# S6E1A1 register map
File version: 1.1
Registers are 8-bit, read-write, reset 0x0 unless marked. A register's access mark holds for its fields unless they carry their own. Offsets are from the block's base; [hi:lo] are bit positions; {n}, {i} and the like mark numbered series; 'fields as' and 'values as' point back to an identical list.

## GPIO — General-purpose I/O ports
Base 0x40033000
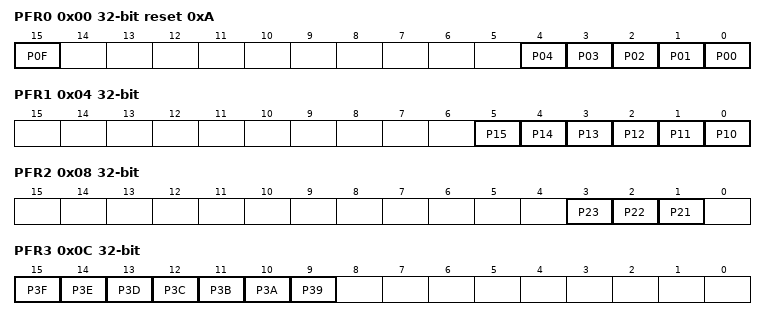
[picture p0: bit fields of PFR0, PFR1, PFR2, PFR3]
0x00 PFR0 32-bit reset 0xA — Port Function Setting Register 0
  [15] P0F — Bit15 of PFR0
  [n] P{n:02} (n=0..4) — Bit{n} of PFR0
0x04 PFR1 32-bit — Port Function Setting Register 1
  [n-10] P{n} (n=10..15) — Bit{n-10} of PFR1
0x08 PFR2 32-bit — Port Function Setting Register 2
  [3] P23 — Bit3 of PFR2
  [2] P22 — Bit2 of PFR2
  [1] P21 — Bit1 of PFR2
0x0C PFR3 32-bit — Port Function Setting Register 3
  [15] P3F — Bit15 of PFR3
  [14] P3E — Bit14 of PFR3
  [13] P3D — Bit13 of PFR3
  [12] P3C — Bit12 of PFR3
  [11] P3B — Bit11 of PFR3
  [10] P3A — Bit10 of PFR3
  [9] P39 — Bit9 of PFR3
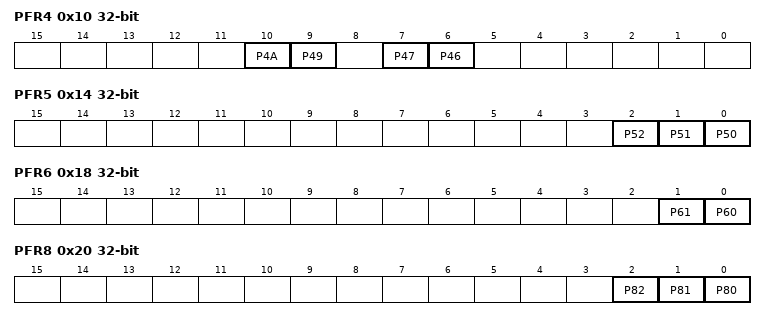
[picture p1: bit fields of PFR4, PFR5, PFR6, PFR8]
0x10 PFR4 32-bit — Port Function Setting Register 4
  [10] P4A — Bit10 of PFR4
  [9] P49 — Bit9 of PFR4
  [7] P47 — Bit7 of PFR4
  [6] P46 — Bit6 of PFR4
0x14 PFR5 32-bit — Port Function Setting Register 5
  [2] P52 — Bit2 of PFR5
  [1] P51 — Bit1 of PFR5
  [0] P50 — Bit0 of PFR5
0x18 PFR6 32-bit — Port Function Setting Register 6
  [1] P61 — Bit1 of PFR6
  [0] P60 — Bit0 of PFR6
0x20 PFR8 32-bit — Port Function Setting Register 8
  [2] P82 — Bit2 of PFR8
  [1] P81 — Bit1 of PFR8
  [0] P80 — Bit0 of PFR8
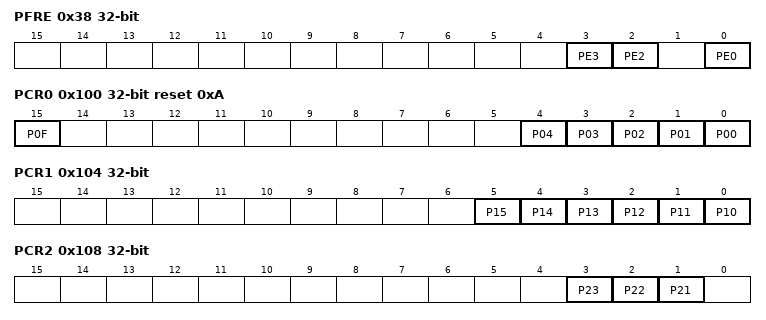
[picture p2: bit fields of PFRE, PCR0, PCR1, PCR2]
0x38 PFRE 32-bit — Port Function Setting Register E
  [3] PE3 — Bit3 of PFRE
  [2] PE2 — Bit2 of PFRE
  [0] PE0 — Bit0 of PFRE
0x100 PCR0 32-bit reset 0xA — Pull-up Setting Register 0
  [15] P0F — Bit15 of PFR0
  [n] P{n:02} (n=0..4) — Bit{n} of PFR0
0x104 PCR1 32-bit — Pull-up Setting Register 1
  [n-10] P{n} (n=10..15) — Bit{n-10} of PFR1
0x108 PCR2 32-bit — Pull-up Setting Register 2
  fields as PFR2
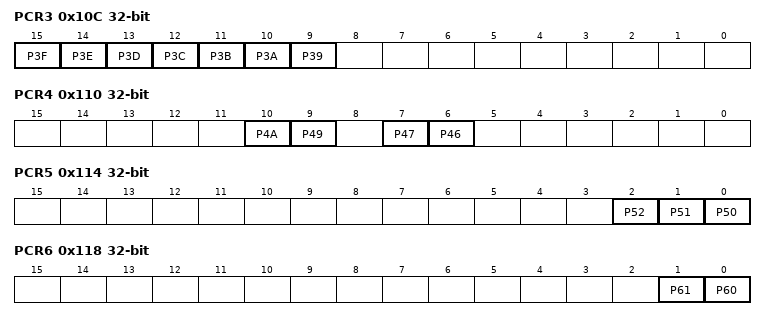
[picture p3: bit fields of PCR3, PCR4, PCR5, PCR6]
0x10C PCR3 32-bit — Pull-up Setting Register 3
  fields as PFR3
0x110 PCR4 32-bit — Pull-up Setting Register 4
  fields as PFR4
0x114 PCR5 32-bit — Pull-up Setting Register 5
  fields as PFR5
0x118 PCR6 32-bit — Pull-up Setting Register 6
  [1] P61 — Bit1 of PFR6
  [0] P60 — Bit0 of PFR6
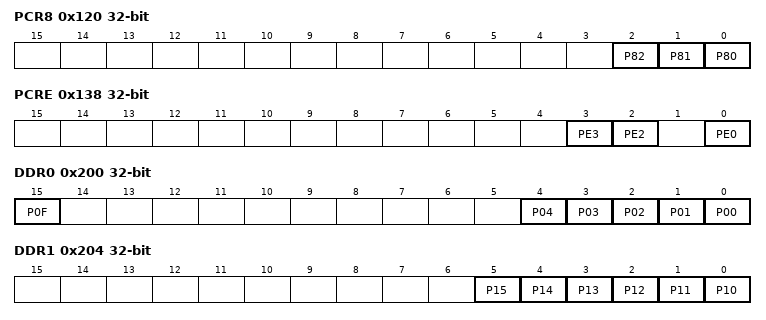
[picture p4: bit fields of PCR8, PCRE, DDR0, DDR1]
0x120 PCR8 32-bit — Pull-up Setting Register 8
  fields as PFR8
0x138 PCRE 32-bit — Pull-up Setting Register E
  fields as PFRE
0x200 DDR0 32-bit — Port input/output Direction Setting Register 0
  [15] P0F — Bit15 of DDR0
  [n] P{n:02} (n=0..4) — Bit{n} of DDR0
0x204 DDR1 32-bit — Port input/output Direction Setting Register 1
  [n-10] P{n} (n=10..15) — Bit{n-10} of PFR1
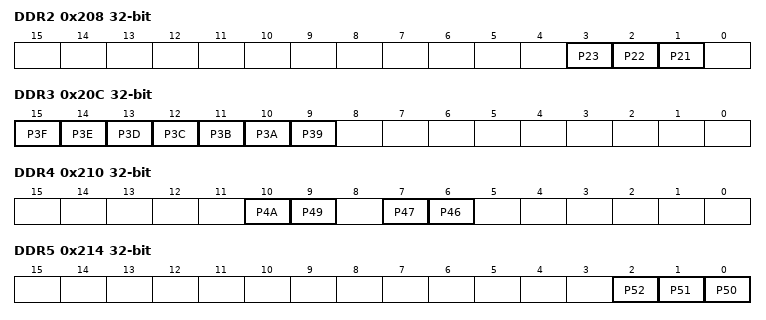
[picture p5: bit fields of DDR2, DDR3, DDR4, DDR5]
0x208 DDR2 32-bit — Port input/output Direction Setting Register 2
  fields as PFR2
0x20C DDR3 32-bit — Port input/output Direction Setting Register 3
  fields as PFR3
0x210 DDR4 32-bit — Port input/output Direction Setting Register 4
  fields as PFR4
0x214 DDR5 32-bit — Port input/output Direction Setting Register 5
  fields as PFR5
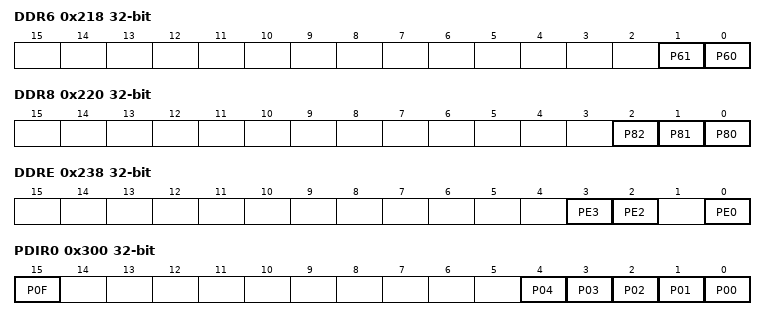
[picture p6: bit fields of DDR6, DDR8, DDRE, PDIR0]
0x218 DDR6 32-bit — Port input/output Direction Setting Register 6
  [1] P61 — Bit1 of PFR6
  [0] P60 — Bit0 of PFR6
0x220 DDR8 32-bit — Port input/output Direction Setting Register 8
  fields as PFR8
0x238 DDRE 32-bit — Port input/output Direction Setting Register E
  fields as PFRE
0x300 PDIR0 32-bit ro — Port Input Data Register 0
  [15] P0F — Bit15 of PDIR0
  [n] P{n:02} (n=0..4) — Bit{n} of PDIR0
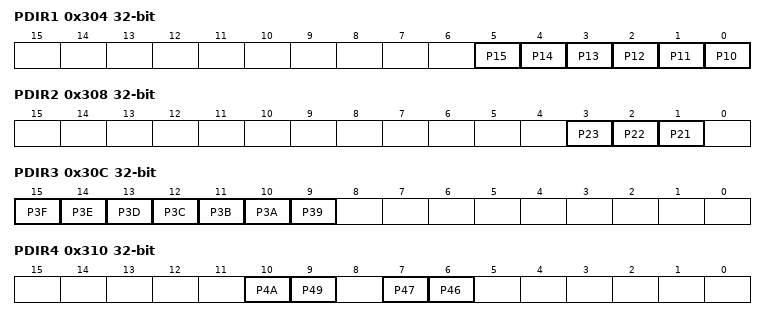
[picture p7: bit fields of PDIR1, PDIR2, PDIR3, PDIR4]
0x304 PDIR1 32-bit ro — Port Input Data Register 1
  [n-10] P{n} (n=10..15) — Bit{n-10} of PDIR1
0x308 PDIR2 32-bit ro — Port Input Data Register 2
  [3] P23 — Bit3 of PDIR2
  [2] P22 — Bit2 of PDIR2
  [1] P21 — Bit1 of PDIR2
0x30C PDIR3 32-bit ro — Port Input Data Register 3
  [15] P3F — Bit15 of PDIR3
  [14] P3E — Bit14 of PDIR3
  [13] P3D — Bit13 of PDIR3
  [12] P3C — Bit12 of PDIR3
  [11] P3B — Bit11 of PDIR3
  [10] P3A — Bit10 of PDIR3
  [9] P39 — Bit9 of PDIR3
0x310 PDIR4 32-bit ro — Port Input Data Register 4
  [10] P4A — Bit10 of PDIR4
  [9] P49 — Bit9 of PDIR4
  [7] P47 — Bit7 of PDIR4
  [6] P46 — Bit6 of PDIR4
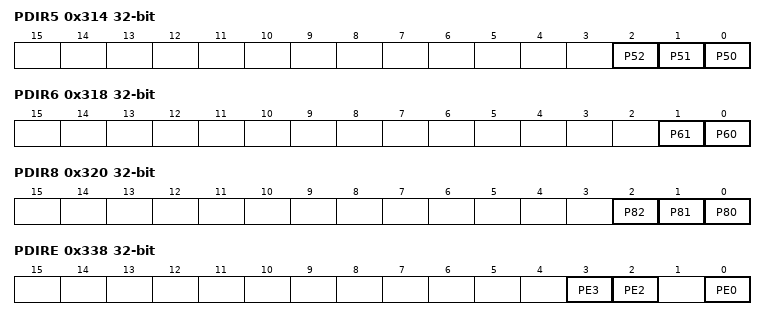
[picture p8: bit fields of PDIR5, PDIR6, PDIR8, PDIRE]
0x314 PDIR5 32-bit ro — Port Input Data Register 5
  [2] P52 — Bit2 of PDIR5
  [1] P51 — Bit1 of PDIR5
  [0] P50 — Bit0 of PDIR5
0x318 PDIR6 32-bit ro — Port Input Data Register 6
  [1] P61 — Bit1 of PDIR6
  [0] P60 — Bit0 of PDIR6
0x320 PDIR8 32-bit ro — Port Input Data Register 8
  [2] P82 — Bit2 of PDIR8
  [1] P81 — Bit1 of PDIR8
  [0] P80 — Bit0 of PDIR8
0x338 PDIRE 32-bit ro — Port Input Data Register E
  [3] PE3 — Bit3 of PDIRE
  [2] PE2 — Bit2 of PDIRE
  [0] PE0 — Bit0 of PDIRE
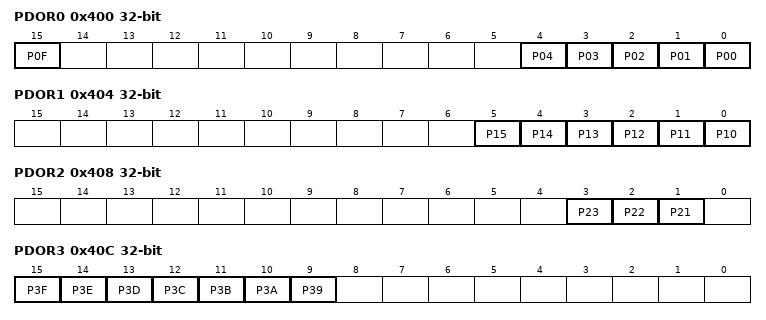
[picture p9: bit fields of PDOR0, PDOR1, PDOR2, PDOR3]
0x400 PDOR0 32-bit — Port Output Data Register 0
  [15] P0F — Bit15 of DDR0
  [n] P{n:02} (n=0..4) — Bit{n} of DDR0
0x404 PDOR1 32-bit — Port Output Data Register 1
  [n-10] P{n} (n=10..15) — Bit{n-10} of PFR1
0x408 PDOR2 32-bit — Port Output Data Register 2
  fields as PFR2
0x40C PDOR3 32-bit — Port Output Data Register 3
  fields as PFR3
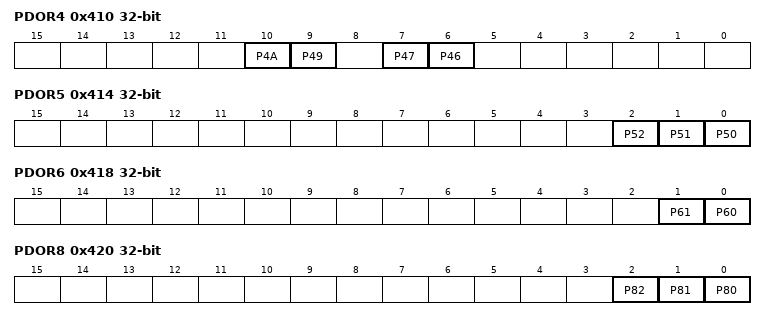
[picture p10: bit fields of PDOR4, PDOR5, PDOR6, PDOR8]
0x410 PDOR4 32-bit — Port Output Data Register 4
  fields as PFR4
0x414 PDOR5 32-bit — Port Output Data Register 5
  fields as PFR5
0x418 PDOR6 32-bit — Port Output Data Register 6
  [1] P61 — Bit1 of PFR6
  [0] P60 — Bit0 of PFR6
0x420 PDOR8 32-bit — Port Output Data Register 8
  fields as PFR8
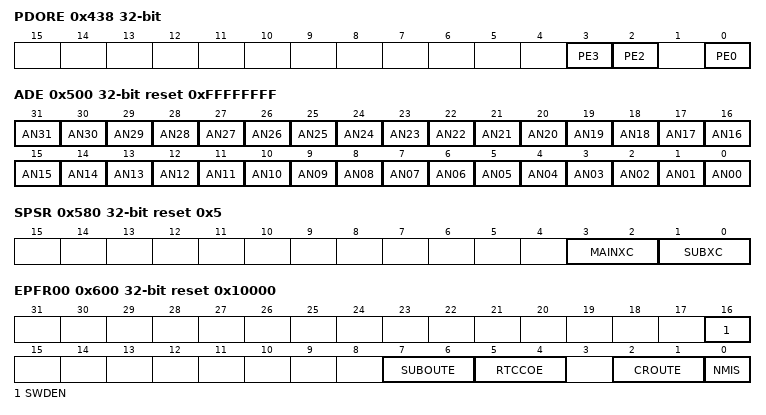
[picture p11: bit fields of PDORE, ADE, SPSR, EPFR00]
0x438 PDORE 32-bit — Port Output Data Register E
  fields as PFRE
0x500 ADE 32-bit reset 0xFFFFFFFF — Analog Input Setting Register
  [31] AN31 — Analog Input Ch.31 Setting Register
  [30] AN30 — Analog Input Ch.30 Setting Register
  [29] AN29 — Analog Input Ch.29 Setting Register
  [28] AN28 — Analog Input Ch.28 Setting Register
  [27] AN27 — Analog Input Ch.27 Setting Register
  [26] AN26 — Analog Input Ch.26 Setting Register
  [25] AN25 — Analog Input Ch.25 Setting Register
  [24] AN24 — Analog Input Ch.24 Setting Register
  [23] AN23 — Analog Input Ch.23 Setting Register
  [22] AN22 — Analog Input Ch.22 Setting Register
  [21] AN21 — Analog Input Ch.21 Setting Register
  [20] AN20 — Analog Input Ch.20 Setting Register
  [19] AN19 — Analog Input Ch.19 Setting Register
  [18] AN18 — Analog Input Ch.18 Setting Register
  [17] AN17 — Analog Input Ch.17 Setting Register
  [16] AN16 — Analog Input Ch.16 Setting Register
  [15] AN15 — Analog Input Ch.15 Setting Register
  [14] AN14 — Analog Input Ch.14 Setting Register
  [13] AN13 — Analog Input Ch.13 Setting Register
  [12] AN12 — Analog Input Ch.12 Setting Register
  [11] AN11 — Analog Input Ch.11 Setting Register
  [10] AN10 — Analog Input Ch.10 Setting Register
  [9] AN09 — Analog Input Ch.9 Setting Register
  [8] AN08 — Analog Input Ch.8 Setting Register
  [7] AN07 — Analog Input Ch.7 Setting Register
  [6] AN06 — Analog Input Ch.6 Setting Register
  [5] AN05 — Analog Input Ch.5 Setting Register
  [4] AN04 — Analog Input Ch.4 Setting Register
  [3] AN03 — Analog Input Ch.3 Setting Register
  [2] AN02 — Analog Input Ch.2 Setting Register
  [1] AN01 — Analog Input Ch.1 Setting Register
  [0] AN00 — Analog Input Ch.0 Setting Register
0x580 SPSR 32-bit reset 0x5 — Special port setting register
  [3:2] MAINXC — Main Clock (Oscillation) Pin Setting Register
  [1:0] SUBXC — Sub Clock (Oscillation) Pin Setting Register
0x600 EPFR00 32-bit reset 0x10000 — Extended Pin Function Setting Register 00
  [16] SWDEN — Serial Wire Debug Function Select bit 0
  [7:6] SUBOUTE — Sub clock divide output function select bit
  [5:4] RTCCOE — RTC clock output select bit
  [2:1] CROUTE — Internal high-speed CR Oscillation Output Function Select bit
  [0] NMIS — NMIX Function Select bit
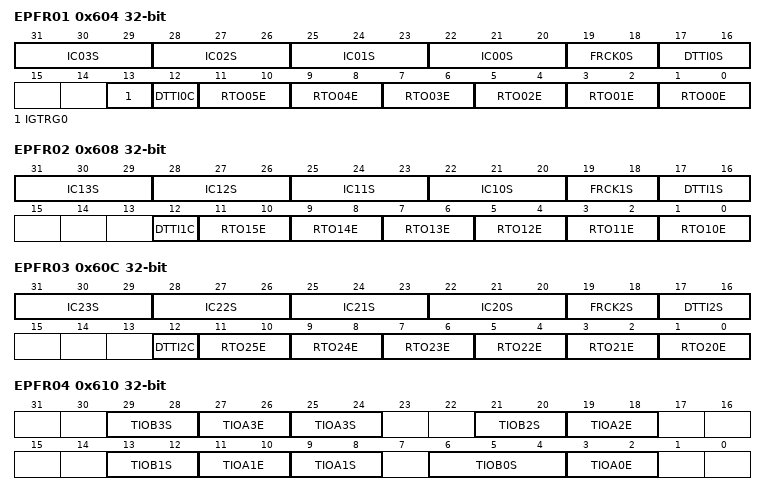
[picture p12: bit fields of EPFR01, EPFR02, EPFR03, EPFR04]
0x604 EPFR01 32-bit — Extended Pin Function Setting Register 01
  [3n+22:3n+20] IC{n:02}S (n=0..3) — IC{n:02} Input Select bits
  [19:18] FRCK0S — FRCK0 Input Select bits
  [17:16] DTTI0S — DTTIX0 Input Select bits
  [13] IGTRG0 — IGTRG0 Input Select bit
  [12] DTTI0C — DTTIX0 Function Select bit
  [2n+1:2n] RTO{n:02}E (n=0..5) — RTO{n:02} Output Select bits
0x608 EPFR02 32-bit — Extended Pin Function Setting Register 02
  [3n-8:3n-10] IC{n}S (n=10..13) — IC{n} Input Select bits
  [19:18] FRCK1S — FRCK1 Input Select bits
  [17:16] DTTI1S — DTTIX1 Input Select bits
  [12] DTTI1C — DTTIX1 Function Select bit
  [2n-19:2n-20] RTO{n}E (n=11..15) — RTO{n} Output Select bits
  [1:0] RTO10E — RTO00 Output Select bits
0x60C EPFR03 32-bit — Extended Pin Function Setting Register 03
  [3n-38:3n-40] IC{n}S (n=20..23) — IC{n} Input Select bits
  [19:18] FRCK2S — FRCK2 Input Select bits
  [17:16] DTTI2S — DTTIX2 Input Select bits
  [12] DTTI2C — DTTIX2 Function Select bit
  [2n-39:2n-40] RTO{n}E (n=20..25) — RTO{n} Output Select bits
0x610 EPFR04 32-bit — Extended Pin Function Setting Register 04
  [29:28] TIOB3S — TIOB3 Input Select bits
  [8n+3:8n+2] TIOA{n}E (n=0..3) — TIOA{n} Output Select bits
  [25:24] TIOA3S — TIOA3 Input Select bits
  [21:20] TIOB2S — TIOB2 Input Select bits
  [13:12] TIOB1S — TIOB1 Input Select bits
  [9:8] TIOA1S — TIOA1 Input Select bits
  [6:4] TIOB0S — TIOB0 Input Select bits
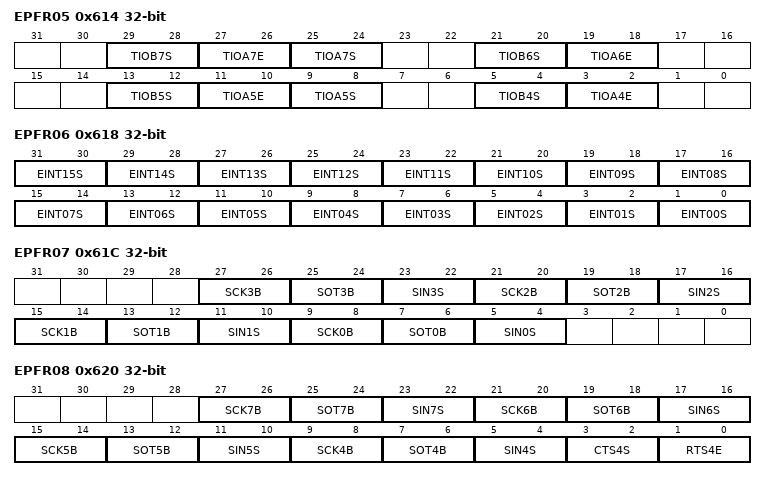
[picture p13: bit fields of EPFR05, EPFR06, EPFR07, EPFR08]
0x614 EPFR05 32-bit — Extended Pin Function Setting Register 05
  [8n-27:8n-28] TIOB{n}S (n=4..7) — TIOB{n} Input Select bits
  [8n-29:8n-30] TIOA{n}E (n=4..7) — TIOA{n} Output Select bits
  [25:24] TIOA7S — TIOA7 Input Select bits
  [9:8] TIOA5S — TIOA5 Input Select bits
0x618 EPFR06 32-bit — Extended Pin Function Setting Register 06
  [2n+1:2n] EINT{n:02}S (n=0..15) — External Interrupt {n:02} Input Select bits
0x61C EPFR07 32-bit — Extended Pin Function Setting Register 07
  [6n+9:6n+8] SCK{n}B (n=0..3) — SCK{n} Input/Output Select bits
  [6n+7:6n+6] SOT{n}B (n=0..3) — SOT{n} Input/Output Select bits
  [6n+5:6n+4] SIN{n}S (n=0..3) — SIN{n} Input Select bits
0x620 EPFR08 32-bit — Extended Pin Function Setting Register 08
  [6n-15:6n-16] SCK{n}B (n=4..7) — SCK{n} Input/Output Select bits
  [6n-17:6n-18] SOT{n}B (n=4..7) — SOT{n} Input/Output Select bits
  [6n-19:6n-20] SIN{n}S (n=4..7) — SIN{n} Input Select bits
  [3:2] CTS4S — CTS4 Input Select bits
  [1:0] RTS4E — RTS4 Output Select bits
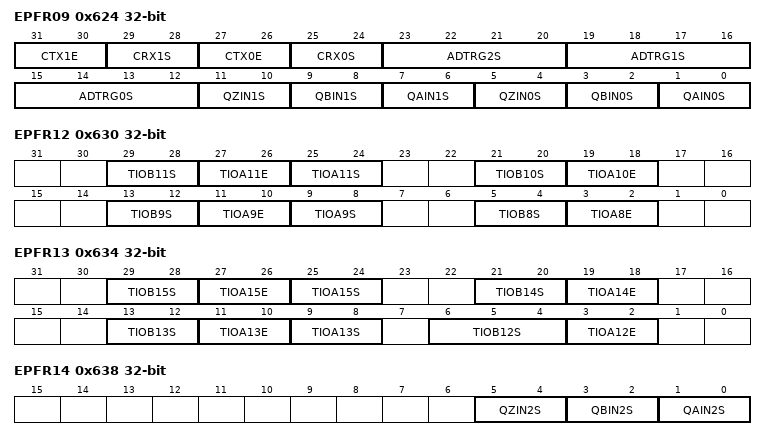
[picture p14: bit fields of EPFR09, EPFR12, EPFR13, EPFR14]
0x624 EPFR09 32-bit — Extended Pin Function Setting Register 09
  [31:30] CTX1E — CTX1E Output Select bits
  [29:28] CRX1S — CRX1S Input Select bits
  [27:26] CTX0E — CTX0E Output Select bits
  [25:24] CRX0S — CRX0S Input Select bits
  [23:20] ADTRG2S — ADTRG2 Input Select bits
  [19:16] ADTRG1S — ADTRG1 Input Select bits
  [15:12] ADTRG0S — ADTRG0 Input Select bits
  [11:10] QZIN1S — QZIN1S Input Select bits
  [9:8] QBIN1S — QBIN1S Input Select bits
  [7:6] QAIN1S — QAIN1S Input Select bits
  [5:4] QZIN0S — QZIN0S Input Select bits
  [3:2] QBIN0S — QBIN0S Input Select bits
  [1:0] QAIN0S — QAIN0S Input Select bits
0x630 EPFR12 32-bit — Extended Pin Function Setting Register 12
  [8n-59:8n-60] TIOB{n}S (n=8..11) — TIOB{n} Input Select bits
  [8n-61:8n-62] TIOA{n}E (n=8..11) — TIOA{n} Output Select bits
  [25:24] TIOA11S — TIOA11 Input Select bits
  [9:8] TIOA9S — TIOA9 Input Select bits
0x634 EPFR13 32-bit (reset mask 0x3F3C3F3C) — Extended Pin Function Setting Register 13
  [29:28] TIOB15S — TIOB15 Input Select bits
  [8n-93:8n-94] TIOA{n}E (n=12..15) — TIOA{n} Output Select bits
  [25:24] TIOA15S — TIOA15 Input Select bits
  [21:20] TIOB14S — TIOB14 Input Select bits
  [13:12] TIOB13S — TIOB13 Input Select bits
  [9:8] TIOA13S — TIOA13 Input Select bits
  [6:4] TIOB12S — TIOB12 Input Select bits
0x638 EPFR14 32-bit — Extended Pin Function Setting Register 14
  [5:4] QZIN2S — QPRC-ch.2 ZIN Input Pin bits
  [3:2] QBIN2S — QPRC-ch.2 BIN Input Pin bits
  [1:0] QAIN2S — QPRC-ch.2 AIN Input Pin bits
0x63C EPFR15 32-bit — Extended Pin Function Setting Register 15
  [2n-31:2n-32] EINT{n}S (n=16..31) — External Interrupt {n} Input Select bits
0x640 EPFR16 32-bit — Extended Pin Function Setting Register 16
  [6n-39:6n-40] SCK{n}B (n=8..11) — SCK{n} Input/Output Select bits
  [6n-41:6n-42] SOT{n}B (n=8..11) — SOT{n} Input/Output Select bits
  [6n-43:6n-44] SIN{n}S (n=8..11) — SIN{n} Input Select bits
0x644 EPFR17 32-bit — Extended Pin Function Setting Register 18
  [6n-63:6n-64] SCK{n}B (n=12..15) — SCK{n} Input/Output Select bits
  [6n-65:6n-66] SOT{n}B (n=12..15) — SOT{n} Input/Output Select bits
  [6n-67:6n-68] SIN{n}S (n=12..15) — SIN{n} Input Select bits
0x648 EPFR18 32-bit — Extended Pin Function Setting Register 18
  [3:2] CECR1B — CEC1 input/output selection bits
  [1:0] CECR0B — CEC0 input/output selection bits
0x654 EPFR21 32-bit — Extended Pin Function Setting Register 21
  [2] QZIN0S — QPRC-ch.0 ZIN Input Pin bits
  [1] QBIN0S — QPRC-ch.0 BIN Input Pin bits
  [0] QAIN0S — QPRC-ch.0 AIN Input Pin bits
0x658 EPFR22 32-bit — Extended Pin Function Setting Register 22
  [15:14] SCS31E — SCS31 Output Select bits
  [13:12] SCS30B — SCS30 Input/Output Select bits
  [7:6] SCS11E — SCS11 Output Select bits
  [5:4] SCS10B — SCS10 Input/Output Select bits
0x700 PZR0 32-bit — Port Pseudo Open Drain Setting Register 0
  [15] P0F — Bit15 of DDR0
  [n] P{n:02} (n=0..4) — Bit{n} of DDR0
0x704 PZR1 32-bit — Port Pseudo Open Drain Setting Register 1
  [n-10] P{n} (n=10..15) — Bit{n-10} of PFR1
0x708 PZR2 32-bit — Port Pseudo Open Drain Setting Register 2
  fields as PFR2
0x70C PZR3 32-bit — Port Pseudo Open Drain Setting Register 3
  fields as PFR3
0x710 PZR4 32-bit — Port Pseudo Open Drain Setting Register 4
  fields as PFR4
0x714 PZR5 32-bit — Port Pseudo Open Drain Setting Register 5
  fields as PFR5
0x718 PZR6 32-bit — Port Pseudo Open Drain Setting Register 6
  [1] P61 — Bit1 of PFR6
  [0] P60 — Bit0 of PFR6
0x720 PZR8 32-bit — Port Pseudo Open Drain Setting Register 8
  fields as PFR8
0x738 PZRE 32-bit — Port Pseudo Open Drain Setting Register E
  fields as PFRE
0x900 FPOER0 32-bit wo — Fast GPIO Output Enable Register 0
  [15] P0F — Bit15 of FPOER0
  [n] P{n:02} (n=0..4) — Bit{n} of FPOER0
0x904 FPOER1 32-bit wo — Fast GPIO Output Enable Register 1
  [n-10] P{n} (n=10..15) — Bit{n-10} of FPOER1
0x908 FPOER2 32-bit wo — Fast GPIO Output Enable Register 2
  [3] P23 — Bit3 of FPOER2
  [2] P22 — Bit2 of FPOER2
  [1] P21 — Bit1 of FPOER2
0x90C FPOER3 32-bit wo — Fast GPIO Output Enable Register 3
  [15] P3F — Bit15 of FPOER3
  [14] P3E — Bit14 of FPOER3
  [13] P3D — Bit13 of FPOER3
  [12] P3C — Bit12 of FPOER3
  [11] P3B — Bit11 of FPOER3
  [10] P3A — Bit10 of FPOER3
  [9] P39 — Bit9 of FPOER3
0x910 FPOER4 32-bit wo — Fast GPIO Output Enable Register 4
  [10] P4A — Bit10 of FPOER4
  [9] P49 — Bit9 of FPOER4
  [7] P47 — Bit7 of FPOER4
  [6] P46 — Bit6 of FPOER4
0x914 FPOER5 32-bit wo — Fast GPIO Output Enable Register 5
  [2] P52 — Bit2 of FPOER5
  [1] P51 — Bit1 of FPOER5
  [0] P50 — Bit0 of FPOER5
0x918 FPOER6 32-bit wo — Fast GPIO Output Enable Register 6
  [1] P61 — Bit1 of FPOER6
  [0] P60 — Bit0 of FPOER6
0x920 FPOER8 32-bit wo — Fast GPIO Output Enable Register 8
  [2] P82 — Bit2 of FPOER8
  [1] P81 — Bit1 of FPOER8
  [0] P80 — Bit0 of FPOER8
0x938 FPOERE 32-bit wo — Fast GPIO Output Enable Register E
  [3] PE3 — Bit3 of FPOERE
  [2] PE2 — Bit2 of FPOERE
  [0] PE0 — Bit0 of FPOERE
